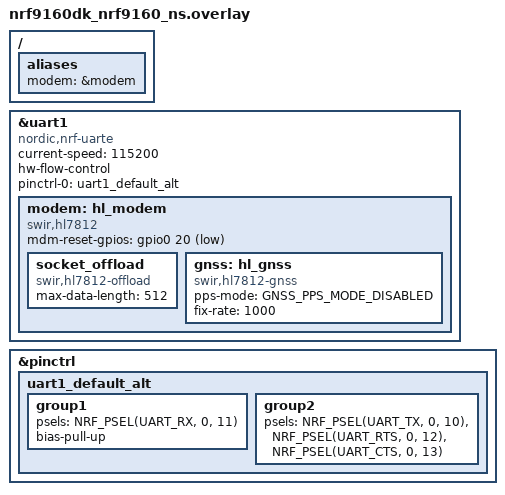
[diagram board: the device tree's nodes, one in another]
/ {
	aliases {
		modem = &modem;
	};
};

&uart1 {
	compatible = "nordic,nrf-uarte";
	current-speed = <115200>;
	hw-flow-control;

	pinctrl-0 = <&uart1_default_alt>;
	status = "okay";

	modem: hl_modem {
		compatible = "swir,hl7812";
		mdm-reset-gpios = <&gpio0 20 GPIO_ACTIVE_LOW>;
		status = "okay";

		socket_offload: socket_offload {
			compatible = "swir,hl7812-offload";
			/* optional properties for future: */
			max-data-length = <512>;
			status = "okay";
		};

		gnss: hl_gnss {
			compatible = "swir,hl7812-gnss";
			pps-mode = "GNSS_PPS_MODE_DISABLED";
			fix-rate = <1000>;
			status = "okay";
		};
	};
};

&pinctrl {
	uart1_default_alt: uart1_default_alt {
		group1 {
			psels = <NRF_PSEL(UART_RX, 0, 11)>;
			bias-pull-up;
		};

		group2 {
			psels = <NRF_PSEL(UART_TX, 0, 10)>,
				<NRF_PSEL(UART_RTS, 0, 12)>,
				<NRF_PSEL(UART_CTS, 0, 13)>;
		};
	};
};
